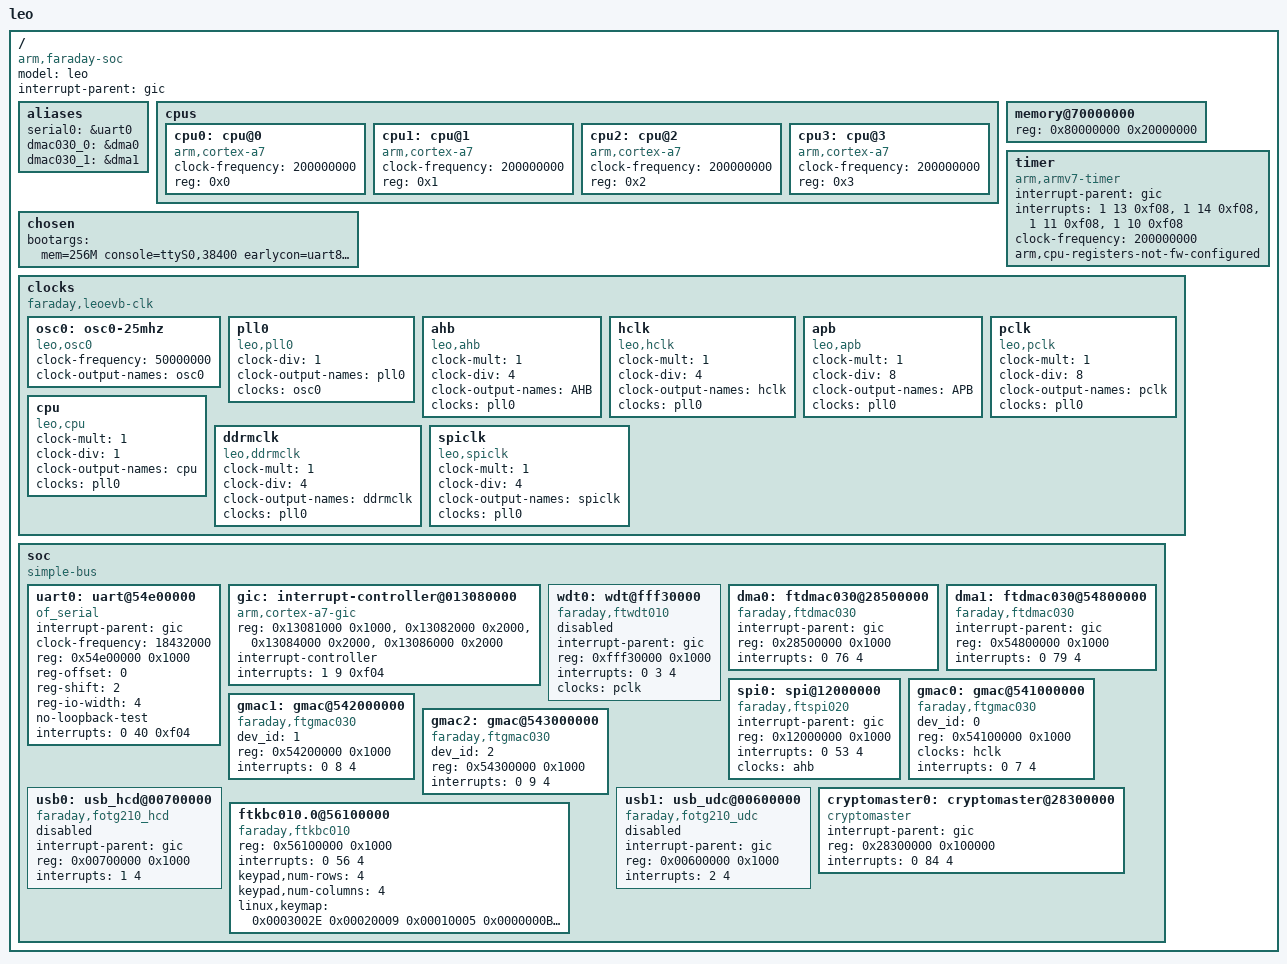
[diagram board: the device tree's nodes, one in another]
/*
 * Copyright (C) 2018 Faraday, Inc. (www.faraday-tech.com)
 *
 * This program is free software; you can redistribute it and/or modify
 * it under the terms of the GNU General Public License version 2 as
 * published by the Free Software Foundation.
 */
 
 /dts-v1/;
 
/*#include <dt-bindings/interrupt-controller/arm-gic.h> */
 
 / {
	model = "leo";
	compatible = "arm,faraday-soc";
	#address-cells = <1>;
	#size-cells = <1>;
	interrupt-parent = <&gic>;
	
	aliases {
		serial0 = &uart0;
		dmac030_0 = &dma0;
		dmac030_1 = &dma1;
	};

	cpus {
		#address-cells = <1>;
		#size-cells = <0>;
	  cpu0: cpu@0 {
		  compatible = "arm,cortex-a7";
		  device_type = "cpu";
      clock-frequency = <200000000>;
		  reg = <0x0>;
	  };
	  cpu1: cpu@1 {
		  compatible = "arm,cortex-a7";
		  device_type = "cpu";
      clock-frequency = <200000000>;
		  reg = <0x1>;
	  };
	  cpu2: cpu@2 {
		  compatible = "arm,cortex-a7";
		  device_type = "cpu";
      clock-frequency = <200000000>;
		  reg = <0x2>;
	  };
	  cpu3: cpu@3 {
		  compatible = "arm,cortex-a7";
		  device_type = "cpu";
      clock-frequency = <200000000>;
		  reg = <0x3>;
	  };
  };
	
	memory@70000000 {
		device_type = "memory";
		reg = <0x80000000 0x20000000>;
	};
	
	chosen {
		bootargs = "mem=256M console=ttyS0,38400 earlycon=uart8250,mmio32,0x54e00000";
	};

	timer {
		compatible = "arm,armv7-timer";
		interrupt-parent = <&gic>;
		interrupts = <1 13 0xf08>,
			     <1 14 0xf08>,
			     <1 11 0xf08>,
			     <1 10 0xf08>;
		clock-frequency = <200000000>;
		arm,cpu-registers-not-fw-configured;
	};
	
	clocks {
		compatible = "faraday,leoevb-clk";
	
		osc0: osc0-25mhz {
			#clock-cells = <0>;
			compatible = "leo,osc0";
			clock-frequency = <50000000>;
			clock-output-names = "osc0";
		};
	
		pll0: pll0 {
			#clock-cells = <0>;
			compatible = "leo,pll0";
			clock-div = <1>;
			clock-output-names = "pll0";
			clocks = <&osc0>;
		};
	
		ahb: ahb {
			#clock-cells = <0>;
			compatible = "leo,ahb";
			clock-mult = <1>;
			clock-div = <4>;
			clock-output-names = "AHB";
			clocks = <&pll0>;
		};
	
		hclk: hclk {
			#clock-cells = <0>;
			compatible = "leo,hclk";
			clock-mult = <1>;
			clock-div = <4>;
			clock-output-names = "hclk";
			clocks = <&pll0>;
		};
	
		apb: apb {
			#clock-cells = <0>;
			compatible = "leo,apb";
			clock-mult = <1>;
			clock-div = <8>;
			clock-output-names = "APB";
			clocks = <&pll0>;
		};
	
		pclk: pclk {
			#clock-cells = <0>;
			compatible = "leo,pclk";
			clock-mult = <1>;
			clock-div = <8>;
			clock-output-names = "pclk";
			clocks = <&pll0>;
		};
	
		cpu: cpu {
			#clock-cells = <0>;
			compatible = "leo,cpu";
			clock-mult = <1>;
			clock-div = <1>;
			clock-output-names = "cpu";
			clocks = <&pll0>;
		};
	
		ddrmclk: ddrmclk {
			#clock-cells = <0>;
			compatible = "leo,ddrmclk";
			clock-mult = <1>;
			clock-div = <4>;
			clock-output-names = "ddrmclk";
			clocks = <&pll0>;
		};
	
		spiclk: spiclk {
			#clock-cells = <0>;
			compatible = "leo,spiclk";
			clock-mult = <1>;
			clock-div = <4>;
			clock-output-names = "spiclk";
			clocks = <&pll0>;
		};
	};
	
	soc {
		#address-cells = <1>;
		#size-cells = <1>;
		compatible = "simple-bus";
		ranges;
	
		uart0: uart@54e00000 {
			compatible = "of_serial", "ns16550a";
			interrupt-parent = <&gic>;
			clock-frequency = <18432000>;
    	reg = <0x54e00000 0x1000>;
			reg-offset = <0>;
			reg-shift = <2>;
			reg-io-width = <4>;
			no-loopback-test;
			interrupts = <0 40 0xf04>;
			/*interrupts = <1 56 0xf04>;*/
			status = "okay";
		};
	
		gic: interrupt-controller@013080000 {
			compatible = "arm,cortex-a7-gic";
			reg = <0x13081000 0x1000>,
			      <0x13082000 0x2000>,
			      <0x13084000 0x2000>,
			      <0x13086000 0x2000>;
			interrupt-controller;
			#interrupt-cells = <3>;
			interrupts = <1 9 0xf04>;
		};

		wdt0: wdt@fff30000 {
			compatible = "faraday,ftwdt010";
			interrupt-parent = <&gic>;
			reg = <0xfff30000 0x1000>;
			interrupts = <0 3 4>;
			clocks = <&pclk>;
			clock-names = "pclk";
			status = "disabled";
		};

		dma0: ftdmac030@28500000 {
			compatible = "faraday,ftdmac030";
			interrupt-parent = <&gic>;
			reg = <0x28500000 0x1000>;
			interrupts = <0 76 4>;
			status = "ok";
		};

		dma1: ftdmac030@54800000 {
			compatible = "faraday,ftdmac030";
			interrupt-parent = <&gic>;
			reg = <0x54800000 0x1000>;
			interrupts = <0 79 4>;
			status = "ok";
		};

		spi0: spi@12000000 {
			compatible = "faraday,ftspi020";
			interrupt-parent = <&gic>;
			/*dma-req-sel = <0>;*/
			/*dma-req-sel = <1>;*/
			reg = <0x12000000 0x1000>;
			interrupts = <0 53 4>;
			clocks = <&ahb>;
			clock-names = "AHB";
			status = "ok";
		};
	
    gmac0: gmac@541000000 {
      compatible = "faraday,ftgmac030";
      dev_id = <0>;
      reg = <0x54100000 0x1000>;
      clocks = <&hclk>;
      interrupts = <0 7 4>;
      status = "ok";
    };

    gmac1: gmac@542000000 {
      compatible = "faraday,ftgmac030";
      dev_id = <1>;
      reg = <0x54200000 0x1000>;
      interrupts = <0 8 4>;
      status = "ok";
    };

    gmac2: gmac@543000000 {
      compatible = "faraday,ftgmac030";
      dev_id = <2>;
      reg = <0x54300000 0x1000>;
      interrupts = <0 9 4>;
      status = "ok";
    };

		usb0: usb_hcd@00700000 {
			compatible = "faraday,fotg210_hcd";
			interrupt-parent = <&gic>;
			reg = <0x00700000 0x1000>;
			interrupts = <1 4>;
			status = "disabled";
		};
	
		usb1: usb_udc@00600000 {
			compatible = "faraday,fotg210_udc";
			interrupt-parent = <&gic>;
			reg = <0x00600000 0x1000>;
			interrupts = <2 4>;
			status = "disabled";
		};

		cryptomaster0:cryptomaster@28300000 {
		  compatible = "cryptomaster";
			interrupt-parent = <&gic>;
			reg = <0x28300000 0x100000>;
			interrupts = <0 84 4>;
		};

    ftkbc010.0@56100000 {
      compatible = "faraday,ftkbc010";
      reg = <0x56100000 0x1000>;
      interrupts = <0 56 4>;
      keypad,num-rows = <4>;
      keypad,num-columns = <4>;
      linux,keymap =
          <0x0003002E
           0x00020009
           0x00010005
           0x0000000B
           0x01030020
           0x0102000A
           0x01010006
           0x01000002
           0x02030012
           0x0202001E
           0x02010007
           0x02000003
           0x03030021
           0x03020030
           0x03010008
           0x03000004>;
    };
	};
};
